# D2522AA register map
Vendor: Dialog; Series: D2522AA; File version: 1.2
CPU: CM0 r1p0, little endian, MPU, FPU, 3 interrupt priority bits
Registers are 32-bit, read-write, reset 0x0 unless marked. A register's access mark holds for its fields unless they carry their own. Offsets are from the block's base; [hi:lo] are bit positions.

## CACHE — CACHE registers
Base 0x100C0000
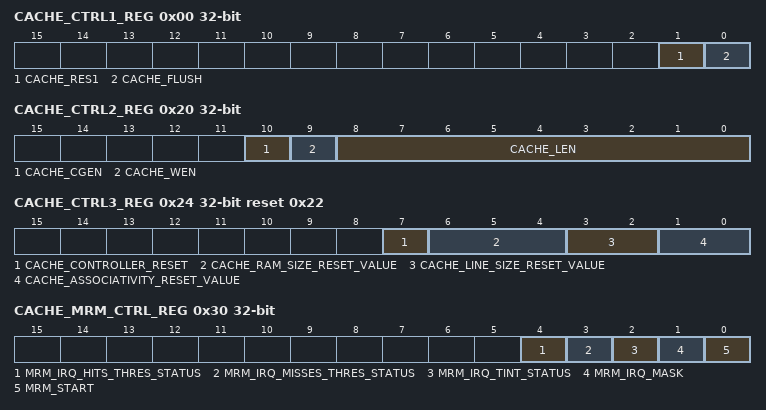
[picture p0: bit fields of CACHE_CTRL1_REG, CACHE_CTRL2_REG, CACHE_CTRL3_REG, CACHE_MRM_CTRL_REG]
0x00 CACHE_CTRL1_REG — Cache control register 1
  [1] CACHE_RES1 — Reserved. Always keep 0.
  [0] CACHE_FLUSH wo — Writing a '1' into this bit, flushes the contents of the tag memories which invalidates the content of the cache memory. The read of this bit is always '0'. Note: The flushing of the cache TAG memory takes 0x100 or 0x200 HCLK cycles for a Cache Data RAM size of 8 KB resp. 16 KB.
0x04 CACHE_LNSIZECFG_REG — Cache line size configuration register
  [1:0] CACHE_LINE — Cache line size: 0: 8 bytes, 1: 16 bytes, 2: 32 bytes, 3: reserved. Note: Flush the cache just after the dynamic (run-time) reconfiguration of the cache with an 8 bytes cache line size: write the value "01" into the cache control register CACHE_CTRL1_REG just after the write of the value "00" into the cache line size configuration register CACHE_LNSIZECFG_REG.
0x08 CACHE_ASSOCCFG_REG reset 0x2 — Cache associativity configuration register
  [1:0] CACHE_ASSOC — Cache associativity: 0: 1-way (direct mapped) 1: 2-way 2: 4-way 3: reserved.
0x20 CACHE_CTRL2_REG — Cache control register 2
  [10] CACHE_CGEN — 0: Cache controller clock gating is not enabled. 1: Cache controller clock gating is enabled (enabling power saving). Note: This bit must be set to '0' (default) when setting the CACHE_FLUSH bit while executing from other than QSPI FLASH cached, e.g. from Booter or SYSRAM.
  [9] CACHE_WEN — 0: Cache Data and TAG memory read only. 1: Cache Data and TAG memory read/write. The TAG and Data memory are only updated by the cache controller. There is no HW protection to prevent unauthorized access by the ARM. Note: When accessing the memory mapped Cache Data and TAG memory (for debugging purposes) only 32 bits access is allowed to the Cache Data memory and only 16 bits access is allowed to the Cache TAG memory.
  [8:0] CACHE_LEN — Length of QSPI FLASH cacheable memory. N*64 KByte. N = 0 to 512 (max. of 32 Mbyte). Setting CACHE_LEN=0 disables the cache. Note 1: The max. relevant CACHE_LEN setting depends on the chosen Flash region (program) size. Note 2: The first block (CACHE_LEN=1) includes the memory space specified by CACHE_FLASH_REG[FLASH_REGION_OFFSET].
0x24 CACHE_CTRL3_REG reset 0x22 — Cache control register 3 (for the Cache Controller configuration reset values)
  [7] CACHE_CONTROLLER_RESET — 0: De-activate the Reset of the Cache Controller. 1: Reset the Cache Controller and take the new configuration reset values (when the reset is released again by changing this bit from '1' to '0'). Note: All CACHE_MRM_* registers are also reset.
  [6:4] CACHE_RAM_SIZE_RESET_VALUE — Cache DATA RAM size reset value: 0: reserved, 1: 8 KB, 2: 16 KB, 3-7: reserved.
  [3:2] CACHE_LINE_SIZE_RESET_VALUE — Cache line size reset value: 0: 8 bytes, 1: 16 bytes, 2: 32 bytes, 3: reserved.
  [1:0] CACHE_ASSOCIATIVITY_RESET_VALUE — Cache associativity reset value: 0: 1-way (direct mapped) 1: 2-way 2: 4-way 3: reserved.
0x28 CACHE_MRM_HITS_REG (reset mask 0x7FFFFFFF) — Cache MRM (Miss Rate Monitor) HITS register
  [31:0] MRM_HITS — Contains the amount of cache hits.
0x2C CACHE_MRM_MISSES_REG (reset mask 0x7FFFFFFF) — Cache MRM (Miss Rate Monitor) MISSES register
  [31:0] MRM_MISSES — Contains the amount of cache misses.
0x30 CACHE_MRM_CTRL_REG — Cache MRM (Miss Rate Monitor) CONTROL register
  [4] MRM_IRQ_HITS_THRES_STATUS — 0: No interrupt is generated. 1: Interrupt (pulse-sensitive) is generated because the number of cache hits reached the programmed threshold (threshold != 0).
  [3] MRM_IRQ_MISSES_THRES_STATUS — 0: No interrupt is generated. 1: Interrupt (pulse-sensitive) is generated because the number of cache misses reached the programmed threshold (threshold != 0).
  [2] MRM_IRQ_TINT_STATUS — 0: No interrupt is generated. 1: Interrupt (pulse-sensitive) is generated because the time interval counter reached the end (time interval != 0).
  [1] MRM_IRQ_MASK — 0: Disables interrupt generation. 1: Enables interrupt generation. Note: The Cache MRM generates a pulse-sensitive interrupt towards the ARM processor,
  [0] MRM_START — 0: Freeze the "misses/hits" counters and reset the time interval counter to the programmed value in CACHE_MRM_TINT_REG. 1: Enables the counters. Note: In case CACHE_MRM_CTRL_REG[MRM_START] is set to '1' and CACHE_MRM_TINT_REG (!=0) is used for the MRM interrupt generation, the time interval counter counts down (on a fixed reference clock of 16 MHz) until it's '0'. At that time CACHE_MRM_CTRL_REG[MRM_START] will be reset automatically to '0' by the MRM hardware and the MRM interrupt will be generated.
0x34 CACHE_MRM_TINT_REG — Cache MRM (Miss Rate Monitor) TIME INTERVAL register
  [18:0] MRM_TINT — Defines the time interval for the monitoring in 32 MHz clock cycles. See also the description of CACHE_MRM_CTRL_REG[MRM_IRQ_TINT_STATUS]. Note: When MRM_TINT=0 (unrealistic value), no interrupt will be generated.
0x38 CACHE_MRM_MISSES_THRES_REG (reset mask 0x7FFFFFFF) — Cache MRM (Miss Rate Monitor) THRESHOLD register
  [31:0] MRM_MISSES_THRES — Defines the misses threshold to trigger the interrupt generation. See also the description of CACHE_MRM_CTRL_REG[MRM_IRQ_MISSES_THRES_STATUS]. Note: When MRM_MISSES_THRES=0 (unrealistic value), no interrupt will be generated.
0x3C CACHE_MRM_HITS_THRES_REG (reset mask 0x7FFFFFFF) — Cache MRM (Miss Rate Monitor) HITS THRESHOLD register
  [31:0] MRM_HITS_THRES — Defines the hits threshold to trigger the interrupt generation. See also the description of CACHE_MRM_CTRL_REG[MRM_IRQ_HITS_THRES_STATUS]. Note: When MRM_HITS_THRES=0 (unrealistic value), no interrupt will be generated.
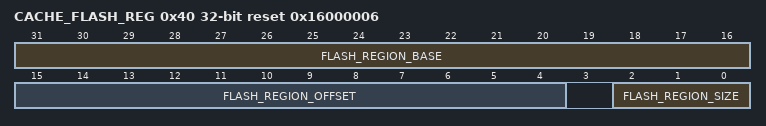
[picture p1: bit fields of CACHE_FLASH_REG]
0x40 CACHE_FLASH_REG reset 0x16000006 (reset mask 0x7FFFFFFF) — Cache Flash program size and base address register
  [31:16] FLASH_REGION_BASE — These bits corresponds with the Flash region base address bits [31:16]. Default value is '0x1600'. The Flash region base address bits [31:25] are fixed to '0x16' and bits [17:16] are fixed to '0x0'. These register bits are retained. Note 1: The updated value takes effect only after a software reset. Note 2 The Flash region base address setting depends on the chosen Flash region size.
  [15:4] FLASH_REGION_OFFSET — Flash region offset address (in words). This value is added to the Flash (CPU) address bits [13:2]. These register bits are retained. Note 1: The updated value takes effect only after a software reset.
  [2:0] FLASH_REGION_SIZE — Flash region size. Default value is '6' (0.5 MBytes). 0 = 32 MBytes, 1 = 16 MBytes, 2 = 8 MBytes, 3 = 4 MBytes, 4 = 2 MBytes, 5 = 1 MBytes, 6 = 0.5 MBytes, 7 = 0.25 MBytes. These register bits are retained. Note 1: The updated value takes effect only after a software reset. Note 2: See for the max. region (program) size the memory map.
0x50 SWD_RESET_REG — SWD HW reset control register
  [0] SWD_HW_RESET_REQ wo — 0: default. 1: HW reset request (from the debugger tool). The register is automatically reset with a HW_RESET. This bit can only be accessed by the debugger software and not by the application.
0x60 CACHE_CPU_M_HADDR_REG (reset mask 0x7FFFFFFF) — Cache CPU Master address (RO) register
  [31:0] CACHE_CPU_M_HADDR ro — Shows the CPU Master address (used in the Cache). Note: Only used for debugging purposes..
0x64 CACHE_M_HADDR_MAP0_REG (reset mask 0x7FFFFFFF) — Cache Master Remapped address (RO) register
  [31:0] CACHE_M_HADDR_MAP0 ro — Shows the Cache Master Remapped to 0x0 (physical) address (used in the Cache). Note: Only used for debugging purposes.
0x68 CACHE_CTRLR_M_HADDR_REG (reset mask 0x7FFFFFFF) — Cache CTRLR Master address (RO) register
  [31:0] CACHE_CTRLR_M_HADDR ro — Shows the Cache Controller Master (physical) QSPI Flash address (used in the Cache) corresponding with the last cache miss. Note: Only used for debugging purposes.
